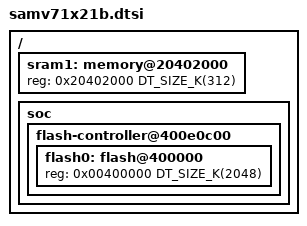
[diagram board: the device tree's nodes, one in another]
/*
 * Copyright (c) 2019-2023 Gerson Fernando Budke <nandojve@gmail.com>
 * Copyright (c) 2020 Stephanos Ioannidis <root@stephanos.io>
 *
 * SPDX-License-Identifier: Apache-2.0
 */

#include <mem.h>
#include <atmel/samv71b.dtsi>

/ {
	sram1: memory@20402000 {
		reg = <0x20402000 DT_SIZE_K(312)>;
	};

	soc {
		flash-controller@400e0c00 {
			flash0: flash@400000 {
				reg = <0x00400000 DT_SIZE_K(2048)>;
			};
		};
	};
};
